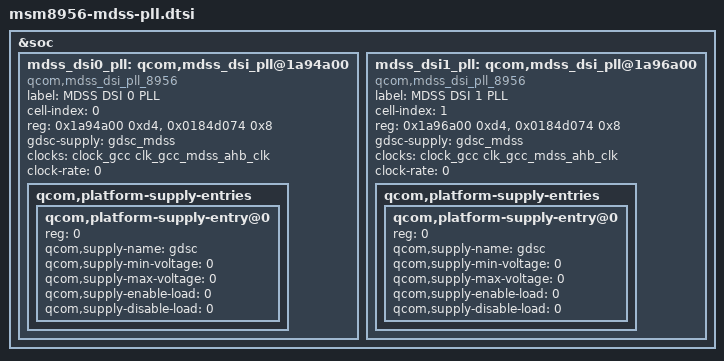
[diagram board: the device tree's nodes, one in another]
// SPDX-License-Identifier: GPL-2.0
// Copyright (c) 2015, The Linux Foundation. All rights reserved.
// Copyright (c) 2022, Benarji Anand <benarji385@gmail.com>

&soc {
	mdss_dsi0_pll: qcom,mdss_dsi_pll@1a94a00 {
		compatible = "qcom,mdss_dsi_pll_8956";
		label = "MDSS DSI 0 PLL";
		cell-index = <0>;
		#clock-cells = <1>;

		reg = <0x1a94a00 0xd4>, <0x0184d074 0x8>;
		reg-names = "pll_base", "gdsc_base";

		gdsc-supply = <&gdsc_mdss>;

		clocks = <&clock_gcc clk_gcc_mdss_ahb_clk>;
		clock-names = "iface_clk";
		clock-rate = <0>;

		qcom,platform-supply-entries {
			#address-cells = <1>;
			#size-cells = <0>;

			qcom,platform-supply-entry@0 {
				reg = <0>;
				qcom,supply-name = "gdsc";
				qcom,supply-min-voltage = <0>;
				qcom,supply-max-voltage = <0>;
				qcom,supply-enable-load = <0>;
				qcom,supply-disable-load = <0>;
			};
		};
	};

	mdss_dsi1_pll: qcom,mdss_dsi_pll@1a96a00 {
		compatible = "qcom,mdss_dsi_pll_8956";
		label = "MDSS DSI 1 PLL";
		cell-index = <1>;
		#clock-cells = <1>;

		reg = <0x1a96a00 0xd4>, <0x0184d074 0x8>;
		reg-names = "pll_base", "gdsc_base";

		gdsc-supply = <&gdsc_mdss>;

		clocks = <&clock_gcc clk_gcc_mdss_ahb_clk>;
		clock-names = "iface_clk";
		clock-rate = <0>;

		qcom,platform-supply-entries {
			#address-cells = <1>;
			#size-cells = <0>;

			qcom,platform-supply-entry@0 {
				reg = <0>;
				qcom,supply-name = "gdsc";
				qcom,supply-min-voltage = <0>;
				qcom,supply-max-voltage = <0>;
				qcom,supply-enable-load = <0>;
				qcom,supply-disable-load = <0>;
			};
		};
	};
};
